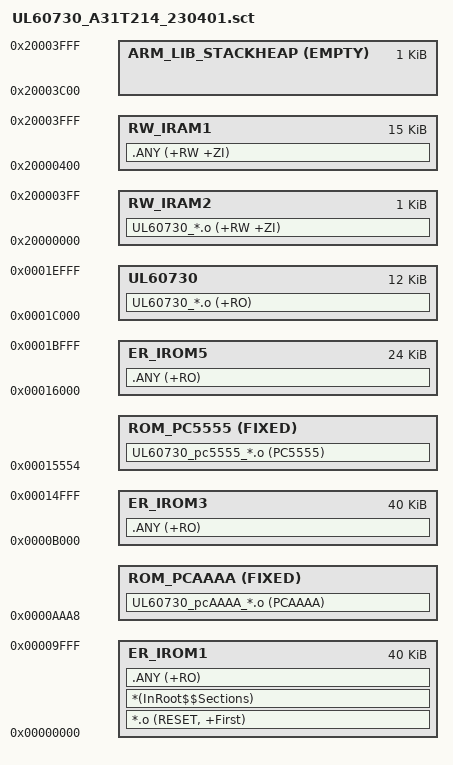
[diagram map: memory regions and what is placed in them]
; /**
; *******************************************************************************
; * @file           UL60730_A31T214_*.sct
; * @author         ABOV R&D Division
; * @brief          UL60730 Library
; *
; * Copyright 2023 ABOV Semiconductor Co.,Ltd. All rights reserved.
; *
; * This file is licensed under terms that are found in the LICENSE file
; * located at Document directory.
; * If this file is delivered or shared without applicable license terms,
; * the terms of the BSD-3-Clause license shall be applied.
; * Reference: https://opensource.org/licenses/BSD-3-Clause
; ******************************************************************************/


;  A31T214
; *************************************************************
; *** Scatter-Loading Description File generated by uVision ***
; *************************************************************	

;_______________________________________ USER 1 ______________________________________________

LR_IROM1 0x00000000 0x0000A000  {			; load region size_region              
	ER_IROM1 0x00000000 0x0000A000  {		; load address = execution address
		*.o (RESET, +First)
		*(InRoot$$Sections)
		.ANY (+RO)
	}
     
	RW_IRAM1 0x20000400  0x00003C00  {		; RW data (16KB - 0x400)
		.ANY (+RW +ZI)
	}
  
	ARM_LIB_STACKHEAP 0x20004000 EMPTY -0x400 {		; STACK   0x20004000-400

	}
}

;_______________________________________ UL60730 - PCAAAA ______________________________________

LR_IROM2 0x0000AAA8  0x00000008  {                                                  
	ROM_PCAAAA 0x0000AAA8	 FIXED  {		
	  UL60730_pcAAAA_*.o (PCAAAA)
	 }
}

;_______________________________________ USER 2 ________________________________________________

LR_IROM3 0x0000B000 0x0000A000  {                                                  
    ER_IROM3 0x0000B000 0x0000A000  {		
   .ANY (+RO)
  }
}

;_______________________________________ UL6030 - PC5555 _______________________________________

LR_IROM4 0x00015554   0x00000008  {                                                
	ROM_PC5555 0x00015554	 FIXED  {		
	  UL60730_pc5555_*.o (PC5555)
	}
}	

;_______________________________________ USER 3 ________________________________________________

LR_IROM5 0x00016000 0x00006000  {                                                  
  ER_IROM5 0x00016000 0x00006000  {			
   .ANY (+RO)
  }
}

;_______________________________________ UL60730 - CLASS B _____________________________________

LR_IROM6 0x0001C000  0x00003000  {
	UL60730  0x0001C000 0x00003000 {		; UL60730 CLASSB SECTION
	  UL60730_*.o (+RO)
	}  

	RW_IRAM2 0x20000000  0x00000400  {		; UL60730 RW data (0x400)
	  UL60730_*.o (+RW +ZI)
	}
}


